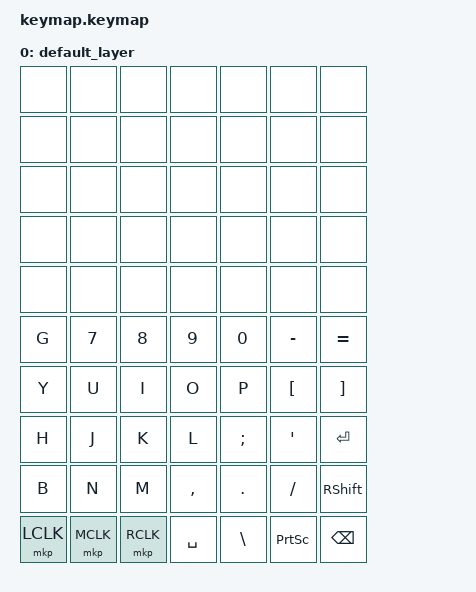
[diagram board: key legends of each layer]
#include <behaviors.dtsi>
#include <dt-bindings/zmk/keys.h>
#include <dt-bindings/zmk/mouse.h>

/ {
    keymap {
        compatible = "zmk,keymap";
        
        default_layer {
            bindings = 
                // 左手35キー（後で設定、今は&none）
                &none &none &none &none &none &none &none
                &none &none &none &none &none &none &none
                &none &none &none &none &none &none &none
                &none &none &none &none &none &none &none
                &none &none &none &none &none &none &none
                
                // 右手35キー（実際のキー配置）
                // 行0 (D3): G 7 8 9 0 - =
                &kp G     &kp N7    &kp N8    &kp N9    &kp N0    &kp MINUS &kp EQUAL
                // 行1 (D9): Y U I O P [ ]
                &kp Y     &kp U     &kp I     &kp O     &kp P     &kp LBKT  &kp RBKT
                // 行2 (P1.07): H J K L ; ' ENTER
                &kp H     &kp J     &kp K     &kp L     &kp SEMI  &kp APOS  &kp RET
                // 行3 (D10): B N M , . / RSHIFT
                &kp B     &kp N     &kp M     &kp COMMA &kp DOT   &kp FSLH  &kp RSHFT
                // 行4 (D4): マウス左 マウス中 マウス右 SPACE バックスラッシュ PRNSCN BS
                &mkp LCLK &mkp MCLK &mkp RCLK &kp SPACE &kp BSLH  &kp PSCRN &kp BSPC
            >;
        };
    };
};
